# STM32F302RDT6 register map
File version: 1.0
Registers are 32-bit, access not given, reset 0x0 unless marked. A register's access mark holds for its fields unless they carry their own. Offsets are from the block's base; [hi:lo] are bit positions; {n}, {i} and the like mark numbered series; 'fields as' and 'values as' point back to an identical list.

## SPI1
Base 0x40013000
Same registers: SPI4 0x40013C00
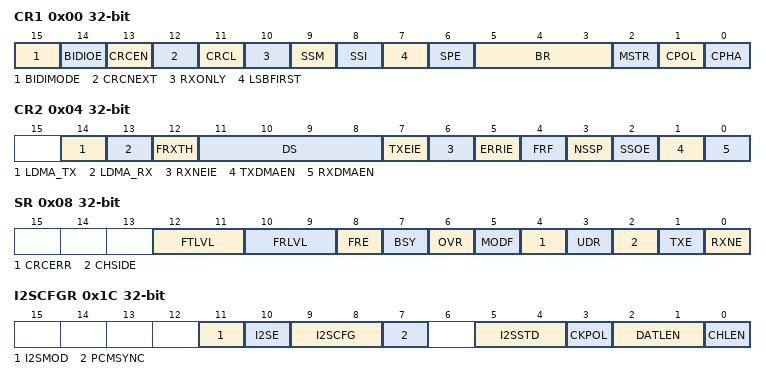
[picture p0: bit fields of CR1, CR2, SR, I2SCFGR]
0x00 CR1
  [15] BIDIMODE, [14] BIDIOE, [13] CRCEN, [12] CRCNEXT, [11] CRCL, [10] RXONLY, [9] SSM, [8] SSI, [7] LSBFIRST, [6] SPE, [5:3] BR, [2] MSTR, [1] CPOL, [0] CPHA
0x04 CR2
  [14] LDMA_TX, [13] LDMA_RX, [12] FRXTH, [11:8] DS, [7] TXEIE, [6] RXNEIE, [5] ERRIE, [4] FRF, [3] NSSP, [2] SSOE, [1] TXDMAEN, [0] RXDMAEN
0x08 SR
  [12:11] FTLVL, [10:9] FRLVL, [8] FRE, [7] BSY, [6] OVR, [5] MODF, [4] CRCERR, [3] UDR, [2] CHSIDE, [1] TXE, [0] RXNE
0x0C DR
  [15:0] DR
0x10 CRCPR
  [15:0] CRCPOLY
0x14 RXCRCR
  [15:0] RXCRC
0x18 TXCRCR
  [15:0] TXCRC
0x1C I2SCFGR
  [11] I2SMOD, [10] I2SE, [9:8] I2SCFG, [7] PCMSYNC, [5:4] I2SSTD, [3] CKPOL, [2:1] DATLEN, [0] CHLEN
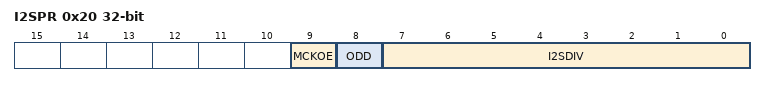
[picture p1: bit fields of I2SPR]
0x20 I2SPR
  [9] MCKOE, [8] ODD, [7:0] I2SDIV

## TIM15
Base 0x40014000
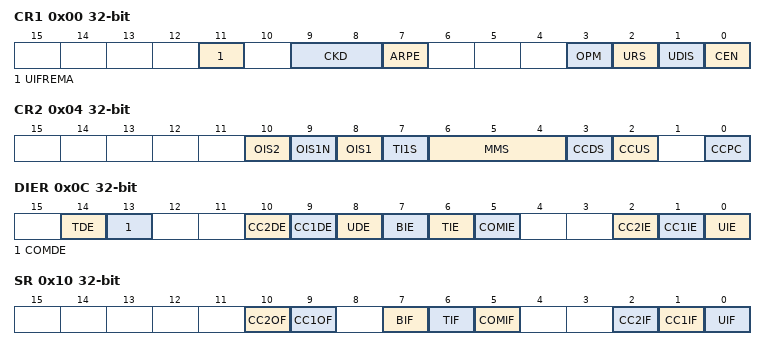
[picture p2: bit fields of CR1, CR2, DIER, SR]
0x00 CR1
  [11] UIFREMA, [9:8] CKD, [7] ARPE, [3] OPM, [2] URS, [1] UDIS, [0] CEN
0x04 CR2
  [10] OIS2, [9] OIS1N, [8] OIS1, [7] TI1S, [6:4] MMS, [3] CCDS, [2] CCUS, [0] CCPC
0x08 SMCR
  [7] MSM, [6:4] TS, [16:0] SMS
0x0C DIER
  [14] TDE, [13] COMDE, [10] CC2DE, [9] CC1DE, [8] UDE, [7] BIE, [6] TIE, [5] COMIE, [2] CC2IE, [1] CC1IE, [0] UIE
0x10 SR
  [10] CC2OF, [9] CC1OF, [7] BIF, [6] TIF, [5] COMIF, [2] CC2IF, [1] CC1IF, [0] UIF
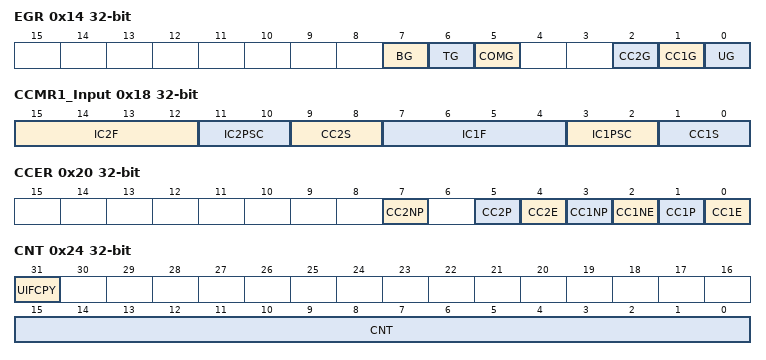
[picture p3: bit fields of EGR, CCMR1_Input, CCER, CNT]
0x14 EGR
  [7] BG, [6] TG, [5] COMG, [2] CC2G, [1] CC1G, [0] UG
0x18 CCMR1_Output
  [15] OC2CE, [24:12] OC2M, [11] OC2PE, [10] OC2FE, [9:8] CC2S, [7] OC!CE, [16:4] OC1M, [3] OC1PE, [2] OC1FE, [1:0] CC1S
0x18 CCMR1_Input
  [15:12] IC2F, [11:10] IC2PSC, [9:8] CC2S, [7:4] IC1F, [3:2] IC1PSC, [1:0] CC1S
0x20 CCER
  [7] CC2NP, [5] CC2P, [4] CC2E, [3] CC1NP, [2] CC1NE, [1] CC1P, [0] CC1E
0x24 CNT
  [31] UIFCPY, [15:0] CNT
0x28 PSC
  [15:0] PSC
0x2C ARR
  [15:0] ARR
0x30 RCR
  [7:0] REP
0x34 CCR1
  [15:0] CCR1
0x38 CCR2
  [15:0] CCR2
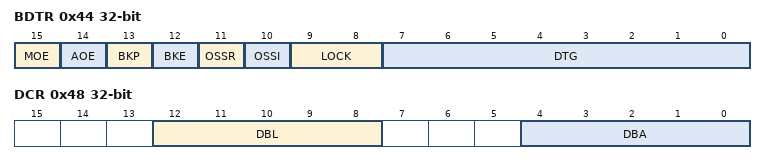
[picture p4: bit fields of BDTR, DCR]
0x44 BDTR
  [15] MOE, [14] AOE, [13] BKP, [12] BKE, [11] OSSR, [10] OSSI, [9:8] LOCK, [7:0] DTG
0x48 DCR
  [12:8] DBL, [4:0] DBA
0x4C DMAR
  [15:0] DMAB

## TIM16
Base 0x40014400
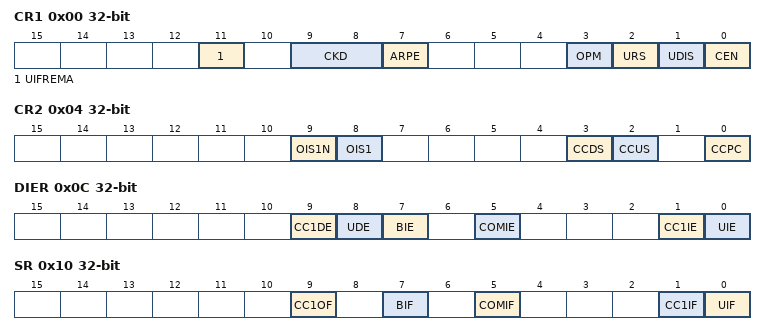
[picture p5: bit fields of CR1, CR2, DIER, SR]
0x00 CR1
  [11] UIFREMA, [9:8] CKD, [7] ARPE, [3] OPM, [2] URS, [1] UDIS, [0] CEN
0x04 CR2
  [9] OIS1N, [8] OIS1, [3] CCDS, [2] CCUS, [0] CCPC
0x0C DIER
  [9] CC1DE, [8] UDE, [7] BIE, [5] COMIE, [1] CC1IE, [0] UIE
0x10 SR
  [9] CC1OF, [7] BIF, [5] COMIF, [1] CC1IF, [0] UIF
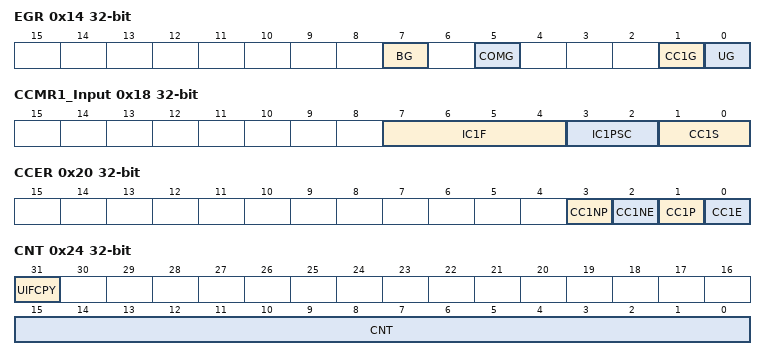
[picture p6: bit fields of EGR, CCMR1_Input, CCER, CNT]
0x14 EGR
  [7] BG, [5] COMG, [1] CC1G, [0] UG
0x18 CCMR1_Output
  [7] OC1CE, [16:4] OC1M, [3] OC1PE, [2] OC1FE, [1:0] CC1S
0x18 CCMR1_Input
  [7:4] IC1F, [3:2] IC1PSC, [1:0] CC1S
0x20 CCER
  [3] CC1NP, [2] CC1NE, [1] CC1P, [0] CC1E
0x24 CNT
  [31] UIFCPY, [15:0] CNT
0x28 PSC
  [15:0] PSC
0x2C ARR
  [15:0] ARR
0x30 RCR
  [7:0] REP
0x34 CCR1
  [15:0] CCR1
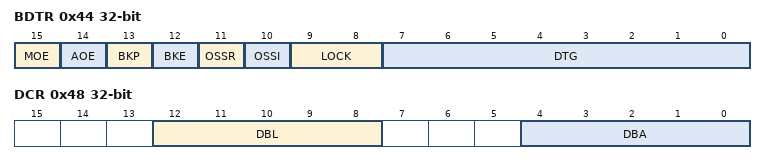
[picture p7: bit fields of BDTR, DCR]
0x44 BDTR
  [15] MOE, [14] AOE, [13] BKP, [12] BKE, [11] OSSR, [10] OSSI, [9:8] LOCK, [7:0] DTG
0x48 DCR
  [12:8] DBL, [4:0] DBA
0x4C DMAR
  [15:0] DMAB
0x50 OR
  [1:0] TI1_RMP

## TIM17
Base 0x40014800
Registers as TIM16, without OR.

## DMA1
Base 0x40020000
Same registers: DMA2 0x40020400
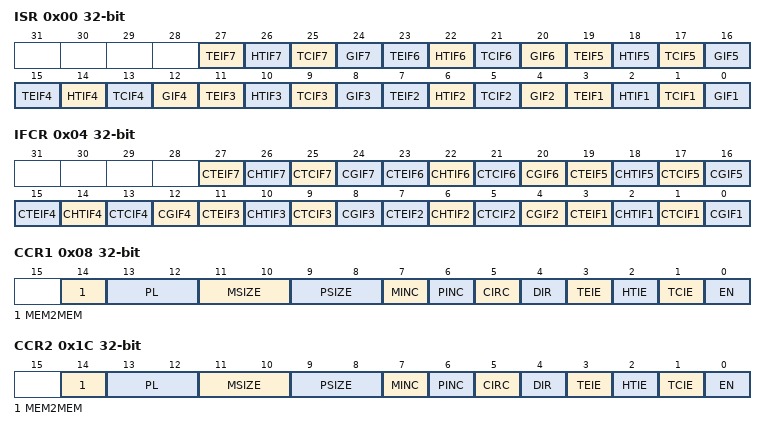
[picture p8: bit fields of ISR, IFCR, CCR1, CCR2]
0x00 ISR
  [4n-1] TEIF{n} (n=1..7), [4n-2] HTIF{n} (n=1..7), [4n-3] TCIF{n} (n=1..7), [4n-4] GIF{n} (n=1..7)
0x04 IFCR
  [4n-1] CTEIF{n} (n=1..7), [4n-2] CHTIF{n} (n=1..7), [4n-3] CTCIF{n} (n=1..7), [4n-4] CGIF{n} (n=1..7)
0x08 CCR1
  [14] MEM2MEM, [13:12] PL, [11:10] MSIZE, [9:8] PSIZE, [7] MINC, [6] PINC, [5] CIRC, [4] DIR, [3] TEIE, [2] HTIE, [1] TCIE, [0] EN
0x0C CNDTR1
  [15:0] NDTR
0x10 CPAR1
  [31:0] PA
{0x0+0x14*i} CMAR{i} (i=1..7)
  [31:0] MA
0x1C CCR2
  fields as CCR1
0x20 CNDTR2
  [15:0] NDTR
0x24 CPAR2
  [31:0] PA
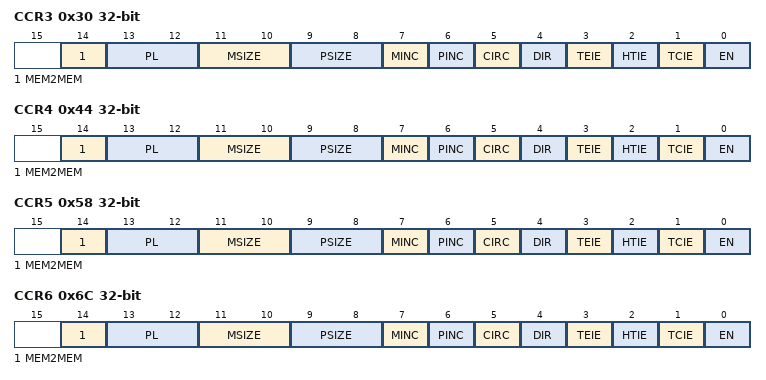
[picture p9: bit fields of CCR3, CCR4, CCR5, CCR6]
0x30 CCR3
  fields as CCR1
0x34 CNDTR3
  [15:0] NDTR
0x38 CPAR3
  [31:0] PA
0x44 CCR4
  fields as CCR1
0x48 CNDTR4
  [15:0] NDTR
0x4C CPAR4
  [31:0] PA
0x58 CCR5
  fields as CCR1
0x5C CNDTR5
  [15:0] NDTR
0x60 CPAR5
  [31:0] PA
0x6C CCR6
  fields as CCR1
0x70 CNDTR6
  [15:0] NDTR
0x74 CPAR6
  [31:0] PA
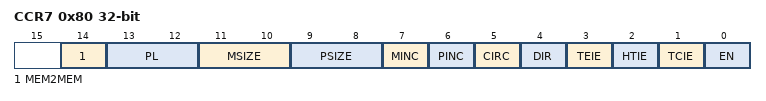
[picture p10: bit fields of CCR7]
0x80 CCR7
  fields as CCR1
0x84 CNDTR7
  [15:0] NDTR
0x88 CPAR7
  [31:0] PA
